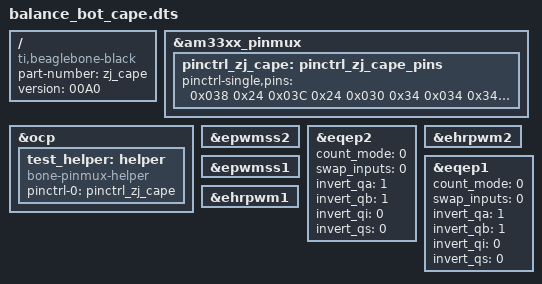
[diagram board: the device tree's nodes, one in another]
/dts-v1/;
/plugin/; 

/ {
    compatible = "ti,beaglebone-black";
    part-number = "zj_cape";
    version = "00A0";

    fragment@0 {
        target = <&am33xx_pinmux>;
        __overlay__ {
pinctrl_zj_cape: pinctrl_zj_cape_pins {
                     pinctrl-single,pins = <
                         /* eQEP */
                         0x038 0x24 /* p8_16 = eqep2_index, mode4 */
                         0x03C 0x24 /* p8_15 = eqep2_strobe, mode4 */ 
                         0x030 0x34 /* p8_12 = eqep2A_in, mode4 */
                         0x034 0x34 /* p8_11 = eqep2B_in, mode4 */
                         0x0D8 0x22 /* p8_31 = eqep1_index, mode2 */
                         0x0DC 0x22 /* p8_32 = eqep1_strobe, mode2 */
                         0x0D0 0x32 /* p8_35 = eqep1A_in, mode2 */
                         0x0D4 0x32 /* p8_33 = eqep1B_in, mode2 */
                         /* PWM */
                         0x020 0x04 /* p8_19 = ehrpwm2A, mode4 */
                         0x024 0x04 /* p8_13 = ehrpwm2B, mode4 */
                         0x048 0x06 /* p9_14 = ehrpwm1A, mode6 */
                         0x04c 0x06 /* p9_16 = ehrpwm1B, mode6 */
                         >;
                 };
        };
    };

    fragment@1 {
        target = <&ocp>;
        __overlay__ {
test_helper: helper {
                 compatible = "bone-pinmux-helper";
                 pinctrl-names = "default";
                 pinctrl-0 = <&pinctrl_zj_cape>;
                 status = "okay";
             };
        };
    };

    fragment@2 {
        target = <&epwmss2>;
        __overlay__ {
            status = "okay";
        };
    };

    fragment@3 {
        target = <&eqep2>;
        __overlay__ {
            status = "okay";
            count_mode = <0>;  /* 0 - Quadrature mode, normal 90 phase offset cha & chb.  1 - Direction mode.  cha input = clock, chb input = direction */
            swap_inputs = <0>; /* Are channel A and channel B swapped? (0 - no, 1 - yes) */
            invert_qa = <1>;   /* Should we invert the channel A input?  */
            invert_qb = <1>;   /* Should we invert the channel B input? I invert these because my encoder outputs drive transistors that pull down the pins */
            invert_qi = <0>;   /* Should we invert the index input? */
            invert_qs = <0>;   /* Should we invert the strobe input? */
        };
    };

    fragment@4 {
        target = <&ehrpwm2>;
        __overlay__ {
            status = "okay";
        };
    };

    fragment@5 {
        target = <&epwmss1>;
        __overlay__ {
            status = "okay";
        };
    };

    fragment@6 {
        target = <&eqep1>;
        __overlay__ {
            status = "okay";
            count_mode = <0>;  /* 0 - Quadrature mode, normal 90 phase offset cha & chb.  1 - Direction mode.  cha input = clock, chb input = direction */
            swap_inputs = <0>; /* Are channel A and channel B swapped? (0 - no, 1 - yes) */
            invert_qa = <1>;   /* Should we invert the channel A input?  */
            invert_qb = <1>;   /* Should we invert the channel B input? I invert these because my encoder outputs drive transistors that pull down the pins */
            invert_qi = <0>;   /* Should we invert the index input? */
            invert_qs = <0>;   /* Should we invert the strobe input? */
        };
    };

    fragment@7 {
        target = <&ehrpwm1>;
        __overlay__ {
            status = "okay";
        };
    };
};
